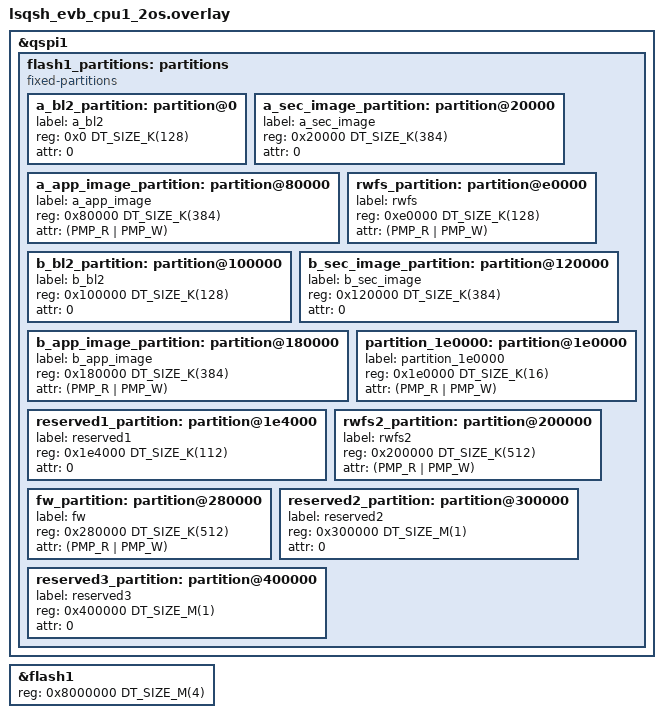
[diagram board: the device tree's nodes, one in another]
&qspi1 {
    flash1_partitions: partitions {
        compatible = "fixed-partitions";
        #address-cells = <1>;
        #size-cells = <1>;

        /* a */
        a_bl2_partition: partition@0 {
            label = "a_bl2";
            reg = <0x0 DT_SIZE_K(128)>;
            attr = <0>;
        };
        a_sec_image_partition: partition@20000 {
            label = "a_sec_image";
            reg = <0x20000 DT_SIZE_K(384)>;
            attr = <0>;
        };
        a_app_image_partition: partition@80000 {
            label = "a_app_image";
            reg = <0x80000 DT_SIZE_K(384)>;
            attr = <(PMP_R | PMP_W)>;
        };
        /* a end */

        rwfs_partition: partition@e0000 {
            label = "rwfs";
            reg = <0xe0000 DT_SIZE_K(128)>;
            attr = <(PMP_R | PMP_W)>;
        };

        /* b */
        b_bl2_partition: partition@100000 {
            label = "b_bl2";
            reg = <0x100000 DT_SIZE_K(128)>;
            attr = <0>;
        };
        b_sec_image_partition: partition@120000 {
            label = "b_sec_image";
            reg = <0x120000 DT_SIZE_K(384)>;
            attr = <0>;
        };
        b_app_image_partition: partition@180000 {
            label = "b_app_image";
            reg = <0x180000 DT_SIZE_K(384)>;
            attr = <(PMP_R | PMP_W)>;
        };
        /* b end */

        partition_1e0000: partition@1e0000 {
            label = "partition_1e0000";
            reg = <0x1e0000 DT_SIZE_K(16)>;
            attr = <(PMP_R | PMP_W)>;
        };
        reserved1_partition: partition@1e4000 {
            label = "reserved1";
            reg = <0x1e4000 DT_SIZE_K(112)>;
            attr = <0>;
        };

        rwfs2_partition: partition@200000 {
            label = "rwfs2";
            reg = <0x200000 DT_SIZE_K(512)>;
            attr = <(PMP_R | PMP_W)>;
        };
        fw_partition: partition@280000 {
            label = "fw";
            reg = <0x280000 DT_SIZE_K(512)>;
            attr = <(PMP_R | PMP_W)>;
        };
        reserved2_partition: partition@300000 {
            label = "reserved2";
            reg = <0x300000 DT_SIZE_M(1)>;
            attr = <0>;
        };
        reserved3_partition: partition@400000 {
            label = "reserved3";
            reg = <0x400000 DT_SIZE_M(1)>;
            attr = <0>;
        };
    };
};

&flash1 {
    reg = <0x8000000 DT_SIZE_M(4)>;
};
